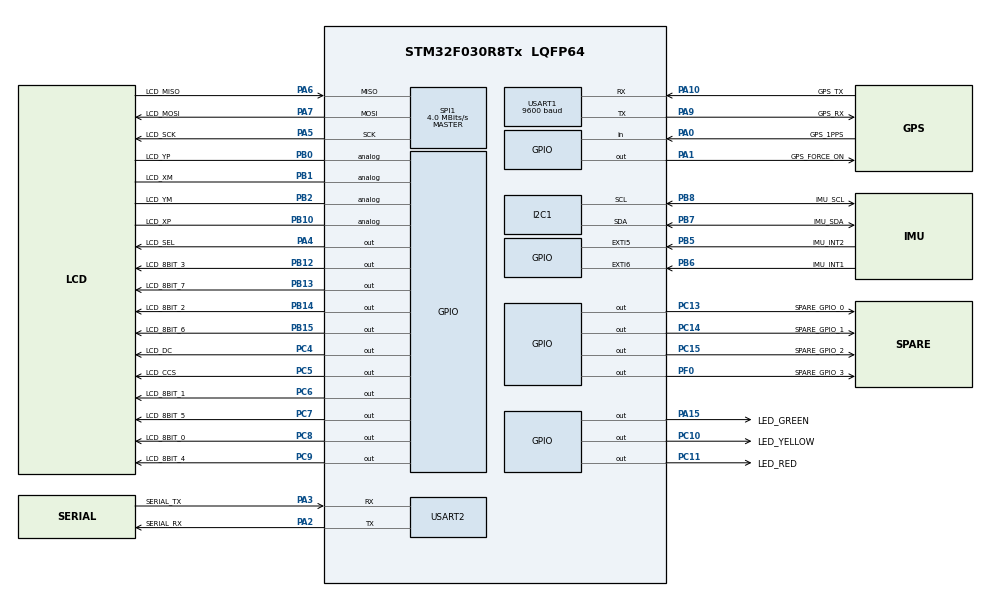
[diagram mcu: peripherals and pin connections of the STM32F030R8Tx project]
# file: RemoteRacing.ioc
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Dma.Request0=USART1_RX
Dma.Request1=USART2_TX
Dma.USART1_RX.0.Direction=DMA_PERIPH_TO_MEMORY
Dma.USART1_RX.0.Instance=DMA1_Channel3
Dma.USART1_RX.0.MemDataAlignment=DMA_MDATAALIGN_BYTE
Dma.USART1_RX.0.MemInc=DMA_MINC_ENABLE
Dma.USART1_RX.0.Mode=DMA_CIRCULAR
Dma.USART1_RX.0.PeriphDataAlignment=DMA_PDATAALIGN_BYTE
Dma.USART1_RX.0.PeriphInc=DMA_PINC_DISABLE
Dma.USART1_RX.0.Priority=DMA_PRIORITY_VERY_HIGH
Dma.USART2_TX.1.Direction=DMA_MEMORY_TO_PERIPH
Dma.USART2_TX.1.Instance=DMA1_Channel4
Dma.USART2_TX.1.MemDataAlignment=DMA_MDATAALIGN_BYTE
Dma.USART2_TX.1.MemInc=DMA_MINC_ENABLE
Dma.USART2_TX.1.Mode=DMA_NORMAL
Dma.USART2_TX.1.PeriphDataAlignment=DMA_PDATAALIGN_BYTE
Dma.USART2_TX.1.PeriphInc=DMA_PINC_DISABLE
Dma.USART2_TX.1.Priority=DMA_PRIORITY_MEDIUM
Mcu.Family=STM32F0
Mcu.Name=STM32F030R8Tx
Mcu.Package=LQFP64
NVIC.DMA1_Channel2_3_IRQn=true\:0\:0\:false\:false\:true\:false\:true
NVIC.DMA1_Channel4_5_IRQn=true\:0\:0\:false\:false\:true\:false\:true
NVIC.TIM1_BRK_UP_TRG_COM_IRQn=true\:0\:0\:false\:false\:true\:false\:true
NVIC.TimeBase=TIM1_BRK_UP_TRG_COM_IRQn
NVIC.TimeBaseIP=TIM1
NVIC.USART2_IRQn=true\:0\:0\:false\:false\:true\:true\:true
PA0.GPIO_Label=GPS_1PPS
PA0.Signal=GPIO_Input
PA1.GPIO_Label=GPS_FORCE_ON
PA1.Signal=GPIO_Output
PA10.GPIO_Label=GPS_TX
PA10.Mode=Asynchronous
PA10.Signal=USART1_RX
PA13.Mode=Serial_Wire
PA13.Signal=SYS_SWDIO
PA14.Mode=Serial_Wire
PA14.Signal=SYS_SWCLK
PA15.GPIO_Label=LED_GREEN
PA15.Signal=GPIO_Output
PA2.GPIO_Label=SERIAL_RX
PA2.Mode=Asynchronous
PA2.Signal=USART2_TX
PA3.GPIO_Label=SERIAL_TX
PA3.Mode=Asynchronous
PA3.Signal=USART2_RX
PA4.GPIO_Label=LCD_SEL
PA4.Signal=GPIO_Output
PA5.GPIO_Label=LCD_SCK
PA5.Mode=Full_Duplex_Master
PA5.Signal=SPI1_SCK
PA6.GPIO_Label=LCD_MISO
PA6.Mode=Full_Duplex_Master
PA6.Signal=SPI1_MISO
PA7.GPIO_Label=LCD_MOSI
PA7.Mode=Full_Duplex_Master
PA7.Signal=SPI1_MOSI
PA9.GPIO_Label=GPS_RX
PA9.Mode=Asynchronous
PA9.Signal=USART1_TX
PB0.GPIO_Label=LCD_YP
PB0.Signal=GPIO_Analog
PB1.GPIO_Label=LCD_XM
PB1.Signal=GPIO_Analog
PB10.GPIO_Label=LCD_XP
PB10.Signal=GPIO_Analog
PB12.GPIO_Label=LCD_8BIT_3
PB12.Signal=GPIO_Output
PB13.GPIO_Label=LCD_8BIT_7
PB13.Signal=GPIO_Output
PB14.GPIO_Label=LCD_8BIT_2
PB14.Signal=GPIO_Output
PB15.GPIO_Label=LCD_8BIT_6
PB15.Signal=GPIO_Output
PB2.GPIO_Label=LCD_YM
PB2.Signal=GPIO_Analog
PB5.GPIO_Label=IMU_INT2
PB5.Signal=GPXTI5
PB6.GPIO_Label=IMU_INT1
PB6.Signal=GPXTI6
PB7.GPIO_Label=IMU_SDA
PB7.Mode=I2C
PB7.Signal=I2C1_SDA
PB8.GPIO_Label=IMU_SCL
PB8.Mode=I2C
PB8.Signal=I2C1_SCL
PC10.GPIO_Label=LED_YELLOW
PC10.Signal=GPIO_Output
PC11.GPIO_Label=LED_RED
PC11.Signal=GPIO_Output
PC13.GPIO_Label=SPARE_GPIO_0
PC13.Signal=GPIO_Output
PC14-OSC32_IN.GPIO_Label=SPARE_GPIO_1
PC14-OSC32_IN.Signal=GPIO_Output
PC15-OSC32_OUT.GPIO_Label=SPARE_GPIO_2
PC15-OSC32_OUT.Signal=GPIO_Output
PC4.GPIO_Label=LCD_DC
PC4.Signal=GPIO_Output
PC5.GPIO_Label=LCD_CCS
PC5.Signal=GPIO_Output
PC6.GPIO_Label=LCD_8BIT_1
PC6.Signal=GPIO_Output
PC7.GPIO_Label=LCD_8BIT_5
PC7.Signal=GPIO_Output
PC8.GPIO_Label=LCD_8BIT_0
PC8.Signal=GPIO_Output
PC9.GPIO_Label=LCD_8BIT_4
PC9.Signal=GPIO_Output
PF0-OSC_IN.GPIO_Label=SPARE_GPIO_3
PF0-OSC_IN.Signal=GPIO_Output
ProjectManager.HeapSize=0x200
ProjectManager.StackSize=0x400
ProjectManager.TargetToolchain=STM32CubeIDE
SPI1.CalculateBaudRate=4.0 MBits/s
SPI1.Direction=SPI_DIRECTION_2LINES
SPI1.Mode=SPI_MODE_MASTER
SPI1.VirtualType=VM_MASTER
USART1.BaudRate=9600
USART1.OverrunDisableParam=ADVFEATURE_OVERRUN_DISABLE
USART1.VirtualMode-Asynchronous=VM_ASYNC
USART2.OverrunDisableParam=ADVFEATURE_OVERRUN_DISABLE
USART2.VirtualMode-Asynchronous=VM_ASYNC
VP_SYS_VS_tim1.Mode=TIM1
board=custom

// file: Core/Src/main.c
/* USER CODE BEGIN Header */
/**
  ******************************************************************************
  * @file           : main.c
  * @brief          : Main program body
  ******************************************************************************
  * @attention
  *
  * <h2><center>&copy; Copyright (c) 2020 STMicroelectronics.
  * All rights reserved.</center></h2>
  *
  * This software component is licensed by ST under BSD 3-Clause license,
  * the "License"; You may not use this file except in compliance with the
  * License. You may obtain a copy of the License at:
  *                        opensource.org/licenses/BSD-3-Clause
  *
  ******************************************************************************
  */
/* USER CODE END Header */

#include "main.h"

/* USER CODE BEGIN PD */
// #define BLE
/* USER CODE END PD */

I2C_HandleTypeDef hi2c1;

SPI_HandleTypeDef hspi1;

UART_HandleTypeDef huart1;
UART_HandleTypeDef huart2;
DMA_HandleTypeDef hdma_usart1_rx;
DMA_HandleTypeDef hdma_usart2_tx;

void SystemClock_Config(void);
static void MX_GPIO_Init(void);
static void MX_DMA_Init(void);
static void MX_I2C1_Init(void);
static void MX_SPI1_Init(void);
static void MX_USART1_UART_Init(void);
static void MX_USART2_UART_Init(void);

int main(void)
{

  /* MCU Configuration--------------------------------------------------------*/

  /* Reset of all peripherals, Initializes the Flash interface and the Systick. */
  HAL_Init();

  /* Configure the system clock */
  SystemClock_Config();

  /* Initialize all configured peripherals */
  MX_GPIO_Init();
  MX_DMA_Init();
  MX_I2C1_Init();
  MX_SPI1_Init();
  MX_USART1_UART_Init();
  MX_USART2_UART_Init();
  /* USER CODE BEGIN 2 */
  initMMA8452Q(0x1D, SCALE_2G, DR_800_Hz);
  gps_init(&huart1);
  ble_init(&huart2);
  RTOS_INIT_TASKS();
  RTOS_INIT();
  // Code should never go past this point
  /* USER CODE END 2 */

  /* Infinite loop */
  while (1)
  {

  }
}

void SystemClock_Config(void)
{
  RCC_OscInitTypeDef RCC_OscInitStruct = {0};
  RCC_ClkInitTypeDef RCC_ClkInitStruct = {0};
  RCC_PeriphCLKInitTypeDef PeriphClkInit = {0};

  /** Initializes the CPU, AHB and APB busses clocks
  */
  RCC_OscInitStruct.OscillatorType = RCC_OSCILLATORTYPE_HSI;
  RCC_OscInitStruct.HSIState = RCC_HSI_ON;
  RCC_OscInitStruct.HSICalibrationValue = RCC_HSICALIBRATION_DEFAULT;
  RCC_OscInitStruct.PLL.PLLState = RCC_PLL_NONE;
  if (HAL_RCC_OscConfig(&RCC_OscInitStruct) != HAL_OK)
  {
    Error_Handler();
  }
  /** Initializes the CPU, AHB and APB busses clocks
  */
  RCC_ClkInitStruct.ClockType = RCC_CLOCKTYPE_HCLK|RCC_CLOCKTYPE_SYSCLK
                              |RCC_CLOCKTYPE_PCLK1;
  RCC_ClkInitStruct.SYSCLKSource = RCC_SYSCLKSOURCE_HSI;
  RCC_ClkInitStruct.AHBCLKDivider = RCC_SYSCLK_DIV1;
  RCC_ClkInitStruct.APB1CLKDivider = RCC_HCLK_DIV1;

  if (HAL_RCC_ClockConfig(&RCC_ClkInitStruct, FLASH_LATENCY_0) != HAL_OK)
  {
    Error_Handler();
  }
  PeriphClkInit.PeriphClockSelection = RCC_PERIPHCLK_USART1|RCC_PERIPHCLK_I2C1;
  PeriphClkInit.Usart1ClockSelection = RCC_USART1CLKSOURCE_PCLK1;
  PeriphClkInit.I2c1ClockSelection = RCC_I2C1CLKSOURCE_HSI;
  if (HAL_RCCEx_PeriphCLKConfig(&PeriphClkInit) != HAL_OK)
  {
    Error_Handler();
  }
}

static void MX_I2C1_Init(void)
{

  hi2c1.Instance = I2C1;
  hi2c1.Init.Timing = 0x2000090E;
  hi2c1.Init.OwnAddress1 = 0;
  hi2c1.Init.AddressingMode = I2C_ADDRESSINGMODE_7BIT;
  hi2c1.Init.DualAddressMode = I2C_DUALADDRESS_DISABLE;
  hi2c1.Init.OwnAddress2 = 0;
  hi2c1.Init.OwnAddress2Masks = I2C_OA2_NOMASK;
  hi2c1.Init.GeneralCallMode = I2C_GENERALCALL_DISABLE;
  hi2c1.Init.NoStretchMode = I2C_NOSTRETCH_DISABLE;
  if (HAL_I2C_Init(&hi2c1) != HAL_OK)
  {
    Error_Handler();
  }
  /** Configure Analogue filter
  */
  if (HAL_I2CEx_ConfigAnalogFilter(&hi2c1, I2C_ANALOGFILTER_ENABLE) != HAL_OK)
  {
    Error_Handler();
  }
  /** Configure Digital filter
  */
  if (HAL_I2CEx_ConfigDigitalFilter(&hi2c1, 0) != HAL_OK)
  {
    Error_Handler();
  }

}

static void MX_SPI1_Init(void)
{

  /* SPI1 parameter configuration*/
  hspi1.Instance = SPI1;
  hspi1.Init.Mode = SPI_MODE_MASTER;
  hspi1.Init.Direction = SPI_DIRECTION_2LINES;
  hspi1.Init.DataSize = SPI_DATASIZE_4BIT;
  hspi1.Init.CLKPolarity = SPI_POLARITY_LOW;
  hspi1.Init.CLKPhase = SPI_PHASE_1EDGE;
  hspi1.Init.NSS = SPI_NSS_SOFT;
  hspi1.Init.BaudRatePrescaler = SPI_BAUDRATEPRESCALER_2;
  hspi1.Init.FirstBit = SPI_FIRSTBIT_MSB;
  hspi1.Init.TIMode = SPI_TIMODE_DISABLE;
  hspi1.Init.CRCCalculation = SPI_CRCCALCULATION_DISABLE;
  hspi1.Init.CRCPolynomial = 7;
  hspi1.Init.CRCLength = SPI_CRC_LENGTH_DATASIZE;
  hspi1.Init.NSSPMode = SPI_NSS_PULSE_ENABLE;
  if (HAL_SPI_Init(&hspi1) != HAL_OK)
  {
    Error_Handler();
  }

}

static void MX_USART1_UART_Init(void)
{

  huart1.Instance = USART1;
  huart1.Init.BaudRate = 9600;
  huart1.Init.WordLength = UART_WORDLENGTH_8B;
  huart1.Init.StopBits = UART_STOPBITS_1;
  huart1.Init.Parity = UART_PARITY_NONE;
  huart1.Init.Mode = UART_MODE_TX_RX;
  huart1.Init.HwFlowCtl = UART_HWCONTROL_NONE;
  huart1.Init.OverSampling = UART_OVERSAMPLING_16;
  huart1.Init.OneBitSampling = UART_ONE_BIT_SAMPLE_DISABLE;
  huart1.AdvancedInit.AdvFeatureInit = UART_ADVFEATURE_RXOVERRUNDISABLE_INIT;
  huart1.AdvancedInit.OverrunDisable = UART_ADVFEATURE_OVERRUN_DISABLE;
  if (HAL_UART_Init(&huart1) != HAL_OK)
  {
    Error_Handler();
  }

}

static void MX_USART2_UART_Init(void)
{

  huart2.Instance = USART2;
  huart2.Init.BaudRate = 38400;
  huart2.Init.WordLength = UART_WORDLENGTH_8B;
  huart2.Init.StopBits = UART_STOPBITS_1;
  huart2.Init.Parity = UART_PARITY_NONE;
  huart2.Init.Mode = UART_MODE_TX_RX;
  huart2.Init.HwFlowCtl = UART_HWCONTROL_NONE;
  huart2.Init.OverSampling = UART_OVERSAMPLING_16;
  huart2.Init.OneBitSampling = UART_ONE_BIT_SAMPLE_DISABLE;
  huart2.AdvancedInit.AdvFeatureInit = UART_ADVFEATURE_RXOVERRUNDISABLE_INIT;
  huart2.AdvancedInit.OverrunDisable = UART_ADVFEATURE_OVERRUN_DISABLE;
  if (HAL_UART_Init(&huart2) != HAL_OK)
  {
    Error_Handler();
  }

}

static void MX_DMA_Init(void)
{

  /* DMA controller clock enable */
  __HAL_RCC_DMA1_CLK_ENABLE();

  /* DMA interrupt init */
  /* DMA1_Channel2_3_IRQn interrupt configuration */
  HAL_NVIC_SetPriority(DMA1_Channel2_3_IRQn, 0, 0);
  HAL_NVIC_EnableIRQ(DMA1_Channel2_3_IRQn);
  /* DMA1_Channel4_5_IRQn interrupt configuration */
  HAL_NVIC_SetPriority(DMA1_Channel4_5_IRQn, 0, 0);
  HAL_NVIC_EnableIRQ(DMA1_Channel4_5_IRQn);

}

static void MX_GPIO_Init(void)
{
  GPIO_InitTypeDef GPIO_InitStruct = {0};

  /* GPIO Ports Clock Enable */
  __HAL_RCC_GPIOC_CLK_ENABLE();
  __HAL_RCC_GPIOF_CLK_ENABLE();
  __HAL_RCC_GPIOA_CLK_ENABLE();
  __HAL_RCC_GPIOB_CLK_ENABLE();

  /*Configure GPIO pin Output Level */
  HAL_GPIO_WritePin(GPIOC, SPARE_GPIO_0_Pin|SPARE_GPIO_1_Pin|SPARE_GPIO_2_Pin|LCD_DC_Pin
                          |LCD_CCS_Pin|LCD_8BIT_1_Pin|LCD_8BIT_5_Pin|LCD_8BIT_0_Pin
                          |LCD_8BIT_4_Pin|LED_YELLOW_Pin|LED_RED_Pin, GPIO_PIN_RESET);

  /*Configure GPIO pin Output Level */
  HAL_GPIO_WritePin(SPARE_GPIO_3_GPIO_Port, SPARE_GPIO_3_Pin, GPIO_PIN_RESET);

  /*Configure GPIO pin Output Level */
  HAL_GPIO_WritePin(GPIOA, GPS_FORCE_ON_Pin|LCD_SEL_Pin|LED_GREEN_Pin, GPIO_PIN_RESET);

  /*Configure GPIO pin Output Level */
  HAL_GPIO_WritePin(GPIOB, LCD_8BIT_3_Pin|LCD_8BIT_7_Pin|LCD_8BIT_2_Pin|LCD_8BIT_6_Pin, GPIO_PIN_RESET);

  /*Configure GPIO pins : SPARE_GPIO_0_Pin SPARE_GPIO_1_Pin SPARE_GPIO_2_Pin LCD_DC_Pin
                           LCD_CCS_Pin LCD_8BIT_1_Pin LCD_8BIT_5_Pin LCD_8BIT_0_Pin
                           LCD_8BIT_4_Pin LED_YELLOW_Pin LED_RED_Pin */
  GPIO_InitStruct.Pin = SPARE_GPIO_0_Pin|SPARE_GPIO_1_Pin|SPARE_GPIO_2_Pin|LCD_DC_Pin
                          |LCD_CCS_Pin|LCD_8BIT_1_Pin|LCD_8BIT_5_Pin|LCD_8BIT_0_Pin
                          |LCD_8BIT_4_Pin|LED_YELLOW_Pin|LED_RED_Pin;
  GPIO_InitStruct.Mode = GPIO_MODE_OUTPUT_PP;
  GPIO_InitStruct.Pull = GPIO_NOPULL;
  GPIO_InitStruct.Speed = GPIO_SPEED_FREQ_LOW;
  HAL_GPIO_Init(GPIOC, &GPIO_InitStruct);

  /*Configure GPIO pin : SPARE_GPIO_3_Pin */
  GPIO_InitStruct.Pin = SPARE_GPIO_3_Pin;
  GPIO_InitStruct.Mode = GPIO_MODE_OUTPUT_PP;
  GPIO_InitStruct.Pull = GPIO_NOPULL;
  GPIO_InitStruct.Speed = GPIO_SPEED_FREQ_LOW;
  HAL_GPIO_Init(SPARE_GPIO_3_GPIO_Port, &GPIO_InitStruct);

  /*Configure GPIO pin : GPS_1PPS_Pin */
  GPIO_InitStruct.Pin = GPS_1PPS_Pin;
  GPIO_InitStruct.Mode = GPIO_MODE_INPUT;
  GPIO_InitStruct.Pull = GPIO_NOPULL;
  HAL_GPIO_Init(GPS_1PPS_GPIO_Port, &GPIO_InitStruct);

  /*Configure GPIO pins : GPS_FORCE_ON_Pin LCD_SEL_Pin LED_GREEN_Pin */
  GPIO_InitStruct.Pin = GPS_FORCE_ON_Pin|LCD_SEL_Pin|LED_GREEN_Pin;
  GPIO_InitStruct.Mode = GPIO_MODE_OUTPUT_PP;
  GPIO_InitStruct.Pull = GPIO_NOPULL;
  GPIO_InitStruct.Speed = GPIO_SPEED_FREQ_LOW;
  HAL_GPIO_Init(GPIOA, &GPIO_InitStruct);

  /*Configure GPIO pins : LCD_YP_Pin LCD_XM_Pin LCD_YM_Pin LCD_XP_Pin */
  GPIO_InitStruct.Pin = LCD_YP_Pin|LCD_XM_Pin|LCD_YM_Pin|LCD_XP_Pin;
  GPIO_InitStruct.Mode = GPIO_MODE_ANALOG;
  GPIO_InitStruct.Pull = GPIO_NOPULL;
  HAL_GPIO_Init(GPIOB, &GPIO_InitStruct);

  /*Configure GPIO pins : LCD_8BIT_3_Pin LCD_8BIT_7_Pin LCD_8BIT_2_Pin LCD_8BIT_6_Pin */
  GPIO_InitStruct.Pin = LCD_8BIT_3_Pin|LCD_8BIT_7_Pin|LCD_8BIT_2_Pin|LCD_8BIT_6_Pin;
  GPIO_InitStruct.Mode = GPIO_MODE_OUTPUT_PP;
  GPIO_InitStruct.Pull = GPIO_NOPULL;
  GPIO_InitStruct.Speed = GPIO_SPEED_FREQ_LOW;
  HAL_GPIO_Init(GPIOB, &GPIO_InitStruct);

  /*Configure GPIO pins : IMU_INT2_Pin IMU_INT1_Pin */
  GPIO_InitStruct.Pin = IMU_INT2_Pin|IMU_INT1_Pin;
  GPIO_InitStruct.Mode = GPIO_MODE_IT_RISING;
  GPIO_InitStruct.Pull = GPIO_NOPULL;
  HAL_GPIO_Init(GPIOB, &GPIO_InitStruct);

}

/* USER CODE BEGIN 4 */
void HAL_UART_RxCpltCallback(UART_HandleTypeDef *huart) {
	if (huart == &huart1) {
		gps_recieve_half();
	}
}
void HAL_UART_RxHalfCpltCallback(UART_HandleTypeDef *huart) {
	if (huart == &huart1) {
		gps_recieve_full();
	}
}

/* USER CODE END 4 */

void HAL_TIM_PeriodElapsedCallback(TIM_HandleTypeDef *htim)
{
  if (htim->Instance == TIM1) {
    HAL_IncTick();
  }
}

void Error_Handler(void)
{
}

/************************ (C) COPYRIGHT STMicroelectronics *****END OF FILE****/
